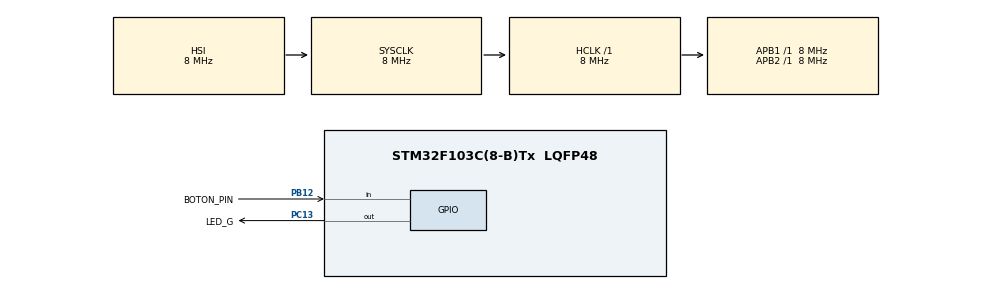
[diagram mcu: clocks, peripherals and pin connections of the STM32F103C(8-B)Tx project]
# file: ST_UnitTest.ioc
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Mcu.Family=STM32F1
Mcu.Name=STM32F103C(8-B)Tx
Mcu.Package=LQFP48
NVIC.PriorityGroup=NVIC_PRIORITYGROUP_4
PA13.Mode=Serial_Wire
PA13.Signal=SYS_JTMS-SWDIO
PA14.Mode=Serial_Wire
PA14.Signal=SYS_JTCK-SWCLK
PB12.GPIO_Label=BOTON_PIN
PB12.GPIO_PuPd=GPIO_PULLUP
PB12.Signal=GPIO_Input
PC13-TAMPER-RTC.GPIO_Label=LED_G
PC13-TAMPER-RTC.GPIO_ModeDefaultOutputPP=GPIO_MODE_OUTPUT_OD
PC13-TAMPER-RTC.GPIO_PuPd=GPIO_NOPULL
PC13-TAMPER-RTC.Signal=GPIO_Output
PC14-OSC32_IN.Mode=LSE-External-Oscillator
PC14-OSC32_IN.Signal=RCC_OSC32_IN
PC15-OSC32_OUT.Mode=LSE-External-Oscillator
PC15-OSC32_OUT.Signal=RCC_OSC32_OUT
PD0-OSC_IN.Mode=HSE-External-Oscillator
PD0-OSC_IN.Signal=RCC_OSC_IN
PD1-OSC_OUT.Mode=HSE-External-Oscillator
PD1-OSC_OUT.Signal=RCC_OSC_OUT
ProjectManager.HeapSize=0x200
ProjectManager.StackSize=0x400
ProjectManager.TargetToolchain=CMake
RCC.AHBFreq_Value=8000000
RCC.APB1Freq_Value=8000000
RCC.APB1TimFreq_Value=8000000
RCC.APB2Freq_Value=8000000
RCC.APB2TimFreq_Value=8000000
RCC.HCLKFreq_Value=8000000
RCC.PLLSourceVirtual=RCC_PLLSOURCE_HSE
RCC.SYSCLKFreq_VALUE=8000000
RCC.USBFreq_Value=16000000
board=custom

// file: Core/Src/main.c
/* USER CODE BEGIN Header */
/**
 ******************************************************************************
 * @file           : main.c
 * @brief          : Main program body
 ******************************************************************************
 * @attention
 *
 * Copyright (c) 2026 STMicroelectronics.
 * All rights reserved.
 *
 * This software is licensed under terms that can be found in the LICENSE file
 * in the root directory of this software component.
 * If no LICENSE file comes with this software, it is provided AS-IS.
 *
 ******************************************************************************
 */
/* USER CODE END Header */
#include "main.h"
#include "gpio.h"

/* USER CODE BEGIN Includes */
#include "led_logic.h"
/* USER CODE END Includes */

/* USER CODE BEGIN PV */
uint32_t delay_duration= 100;

/* USER CODE END PV */

void SystemClock_Config(void);

/* USER CODE BEGIN 0 */
void HAL_GPIO_EXTI_Callback(uint16_t GPIO_Pin){
	if(GPIO_Pin == BUTTON1_PIN){
		if(delay_duration < 100) delay_duration= 100;
		delay_duration*= 4;
		if(delay_duration > 2000) delay_duration= 100;
	}else{
	}
}

/* USER CODE END 0 */

int main(void)
{

  /* MCU Configuration--------------------------------------------------------*/

  /* Reset of all peripherals, Initializes the Flash interface and the Systick. */
  HAL_Init();

  /* Configure the system clock */
  SystemClock_Config();

  /* Initialize all configured peripherals */
  MX_GPIO_Init();
  /* USER CODE BEGIN 2 */
  led_logic_init();
  /* USER CODE END 2 */

  /* Infinite loop */
  /* USER CODE BEGIN WHILE */
	while(1){
    led_logic_update();
    /* USER CODE END WHILE */

	}
}

void SystemClock_Config(void)
{
  RCC_OscInitTypeDef RCC_OscInitStruct = {0};
  RCC_ClkInitTypeDef RCC_ClkInitStruct = {0};

  /** Initializes the RCC Oscillators according to the specified parameters
  * in the RCC_OscInitTypeDef structure.
  */
  RCC_OscInitStruct.OscillatorType = RCC_OSCILLATORTYPE_HSI;
  RCC_OscInitStruct.HSIState = RCC_HSI_ON;
  RCC_OscInitStruct.HSICalibrationValue = RCC_HSICALIBRATION_DEFAULT;
  RCC_OscInitStruct.PLL.PLLState = RCC_PLL_NONE;
  if (HAL_RCC_OscConfig(&RCC_OscInitStruct) != HAL_OK)
  {
    Error_Handler();
  }

  /** Initializes the CPU, AHB and APB buses clocks
  */
  RCC_ClkInitStruct.ClockType = RCC_CLOCKTYPE_HCLK|RCC_CLOCKTYPE_SYSCLK
                              |RCC_CLOCKTYPE_PCLK1|RCC_CLOCKTYPE_PCLK2;
  RCC_ClkInitStruct.SYSCLKSource = RCC_SYSCLKSOURCE_HSI;
  RCC_ClkInitStruct.AHBCLKDivider = RCC_SYSCLK_DIV1;
  RCC_ClkInitStruct.APB1CLKDivider = RCC_HCLK_DIV1;
  RCC_ClkInitStruct.APB2CLKDivider = RCC_HCLK_DIV1;

  if (HAL_RCC_ClockConfig(&RCC_ClkInitStruct, FLASH_LATENCY_0) != HAL_OK)
  {
    Error_Handler();
  }
}

void Error_Handler(void)
{
	__disable_irq();
	while(1){
	}
}
#ifdef USE_FULL_ASSERT
/**
  * @brief  Reports the name of the source file and the source line number
  *         where the assert_param error has occurred.
  * @param  file: pointer to the source file name
  * @param  line: assert_param error line source number
  * @retval None
  */
void assert_failed(uint8_t *file, uint32_t line)
{
  /* USER CODE BEGIN 6 */
	/* Por medio de Debugger, revise el contenido de file y line de esta funcion
	 */
	while(1);
  /* USER CODE END 6 */
}
#endif /* USE_FULL_ASSERT */
